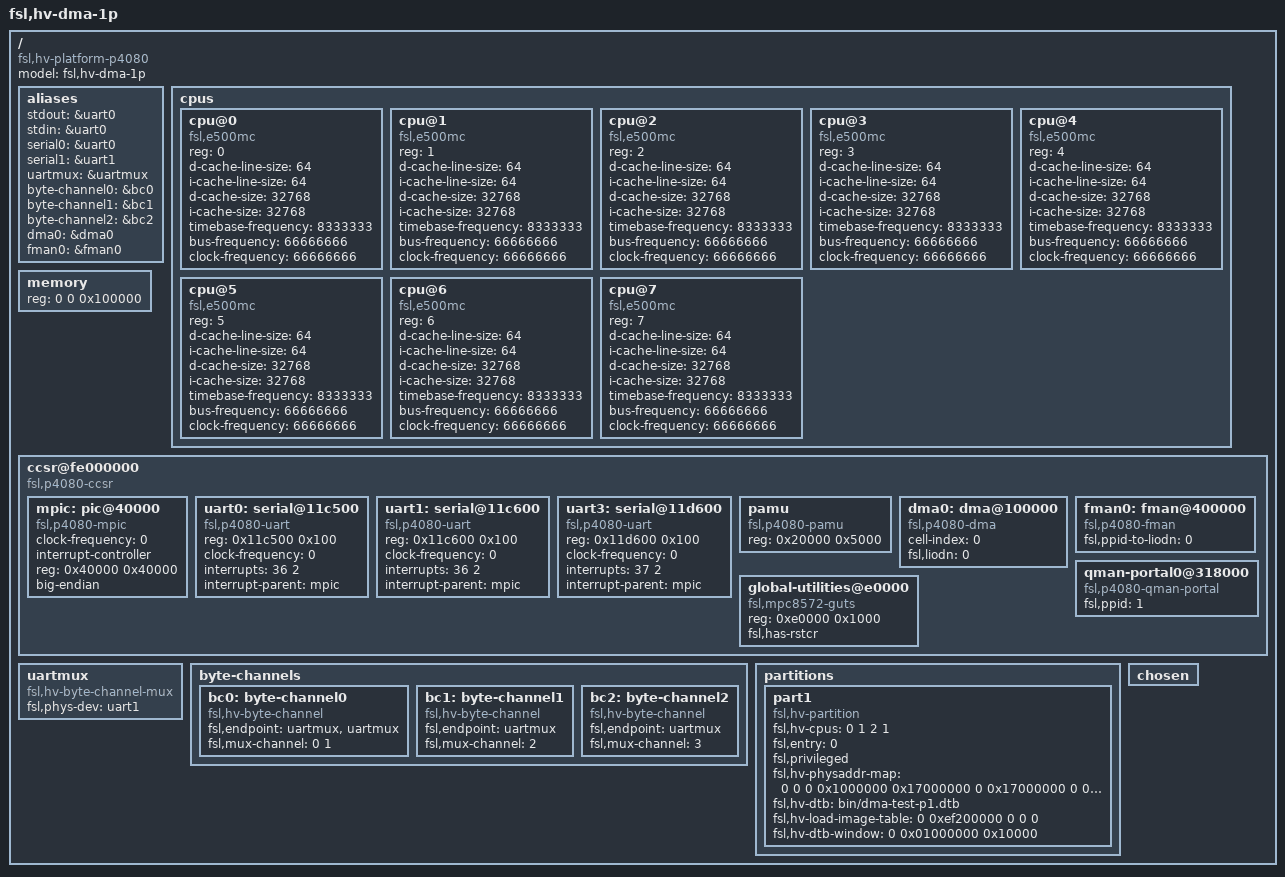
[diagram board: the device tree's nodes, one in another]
/dts-v1/;

/ {
	compatible = "fsl,hv-platform-p4080";
	model = "fsl,hv-dma-1p";
	#address-cells = <2>;
	#size-cells = <1>;

	aliases {
		stdout = &uart0;
		stdin = &uart0;
		serial0 = &uart0;
		serial1 = &uart1;
		uartmux = &uartmux;
		byte-channel0 = &bc0;
		byte-channel1 = &bc1;
		byte-channel2 = &bc2;
		dma0 = &dma0;
		fman0 = &fman0;
	};

	cpus {
		#address-cells = <1>;
		#size-cells = <0>;

		cpu@0 {
			device_type = "cpu";
			compatible = "fsl,e500mc";
			reg = <0>;
			d-cache-line-size = <64>;
			i-cache-line-size = <64>;
			d-cache-size = <32768>;
			i-cache-size = <32768>;
			timebase-frequency = <8333333>;
			bus-frequency = <66666666>;
			clock-frequency = <66666666>;
		};

		cpu@1 {
			device_type = "cpu";
			compatible = "fsl,e500mc";
			reg = <1>;
			d-cache-line-size = <64>;
			i-cache-line-size = <64>;
			d-cache-size = <32768>;
			i-cache-size = <32768>;
			timebase-frequency = <8333333>;
			bus-frequency = <66666666>;
			clock-frequency = <66666666>;
		};

		cpu@2 {
			device_type = "cpu";
			compatible = "fsl,e500mc";
			reg = <2>;
			d-cache-line-size = <64>;
			i-cache-line-size = <64>;
			d-cache-size = <32768>;
			i-cache-size = <32768>;
			timebase-frequency = <8333333>;
			bus-frequency = <66666666>;
			clock-frequency = <66666666>;
		};

		cpu@3 {
			device_type = "cpu";
			compatible = "fsl,e500mc";
			reg = <3>;
			d-cache-line-size = <64>;
			i-cache-line-size = <64>;
			d-cache-size = <32768>;
			i-cache-size = <32768>;
			timebase-frequency = <8333333>;
			bus-frequency = <66666666>;
			clock-frequency = <66666666>;
		};

		cpu@4 {
			device_type = "cpu";
			compatible = "fsl,e500mc";
			reg = <4>;
			d-cache-line-size = <64>;
			i-cache-line-size = <64>;
			d-cache-size = <32768>;
			i-cache-size = <32768>;
			timebase-frequency = <8333333>;
			bus-frequency = <66666666>;
			clock-frequency = <66666666>;
		};

		cpu@5 {
			device_type = "cpu";
			compatible = "fsl,e500mc";
			reg = <5>;
			d-cache-line-size = <64>;
			i-cache-line-size = <64>;
			d-cache-size = <32768>;
			i-cache-size = <32768>;
			timebase-frequency = <8333333>;
			bus-frequency = <66666666>;
			clock-frequency = <66666666>;
		};

		cpu@6 {
			device_type = "cpu";
			compatible = "fsl,e500mc";
			reg = <6>;
			d-cache-line-size = <64>;
			i-cache-line-size = <64>;
			d-cache-size = <32768>;
			i-cache-size = <32768>;
			timebase-frequency = <8333333>;
			bus-frequency = <66666666>;
			clock-frequency = <66666666>;
		};

		cpu@7 {
			device_type = "cpu";
			compatible = "fsl,e500mc";
			reg = <7>;
			d-cache-line-size = <64>;
			i-cache-line-size = <64>;
			d-cache-size = <32768>;
			i-cache-size = <32768>;
			timebase-frequency = <8333333>;
			bus-frequency = <66666666>;
			clock-frequency = <66666666>;
		};
	};

	memory {
		reg = <0 0 0x100000>;
		device_type = "memory";
	};

	ccsr@fe000000 {
		#address-cells = <1>;
		#size-cells = <1>;
		compatible = "fsl,p4080-ccsr", "simple-bus";
		ranges = <0 0 0xfe000000 0x400000>;

		mpic: pic@40000 {
			clock-frequency = <0>;
			interrupt-controller;
			#address-cells = <0>;
			#interrupt-cells = <2>;
			reg = <0x40000 0x40000>;
			compatible = "fsl,p4080-mpic", "fsl,mpic",
			             "chrp,open-pic";
			device_type = "open-pic";
			big-endian;
		};
		
		uart0: serial@11c500 {
			device_type = "serial";
			compatible = "fsl,p4080-uart", "fsl,ns16550", "ns16550";
			reg = <0x11c500 0x100>;
			clock-frequency = <0>;
			interrupts = <36 2>;
			interrupt-parent = <&mpic>;
		};

		uart1: serial@11c600 {
			device_type = "serial";
			compatible = "fsl,p4080-uart", "fsl,ns16550", "ns16550";
			reg = <0x11c600 0x100>;
			clock-frequency = <0>;
			interrupts = <36 2>;
			interrupt-parent = <&mpic>;
		};

		uart3: serial@11d600 {
			device_type = "serial";
			compatible = "fsl,p4080-uart", "fsl,ns16550", "ns16550";
			reg = <0x11d600 0x100>;
			clock-frequency = <0>;
			interrupts = <37 2>;
			interrupt-parent = <&mpic>;
		};

		pamu {

			compatible = "fsl,p4080-pamu";
			reg = <0x20000 0x5000>;
		};

		dma0: dma@100000 {
			#address-cells = <1>;
			#size-cells = <1>;
			compatible = "fsl,p4080-dma";
			cell-index = <0>;
			fsl,liodn = <0>;
		};

		fman0: fman@400000 {
			compatible = "fsl,p4080-fman";
			fsl,ppid-to-liodn = <0>;
		};

		qman-portal0@318000 {
			compatible = "fsl,p4080-qman-portal";
			fsl,ppid = <1>;
		};

		global-utilities@e0000 {	//global utilities block
			compatible = "fsl,mpc8572-guts";
			reg = <0xe0000 0x1000>;
			fsl,has-rstcr;
		};
	};

	uartmux: uartmux {
		compatible = "fsl,hv-byte-channel-mux";
		fsl,phys-dev = <&uart1>;
	};

	byte-channels {
		/* bc0 here is a weird case for testing purposes.
		 * It sets up a loopback in the mux, so that
		 * data coming in channel 0 goes out channel 1.
		 * bc0 is _not_ usable by a guest.
		 */
		bc0: byte-channel0 {
			compatible = "fsl,hv-byte-channel";
			fsl,endpoint = <&uartmux &uartmux>;
			fsl,mux-channel = <0 1>;
		};

		bc1: byte-channel1 {
			compatible = "fsl,hv-byte-channel";
			fsl,endpoint = <&uartmux>;
			fsl,mux-channel = <2>;
		};

		bc2: byte-channel2 {
			compatible = "fsl,hv-byte-channel";
			fsl,endpoint = <&uartmux>;
			fsl,mux-channel = <3>;
		};
	};

	partitions {
		part1 {
			compatible = "fsl,hv-partition";
			fsl,hv-cpus = <0 1 2 1>;
			fsl,entry = <0>;
			fsl,privileged;
			fsl,hv-physaddr-map = <0 0 0 0x1000000 0x17000000
			                       0 0x17000000 0 0x20000000 0x1000000>;
			fsl,hv-dtb = /incbin/("bin/dma-test-p1.dtb");
			fsl,hv-load-image-table = <0 0xef200000 0 0 0>;
			fsl,hv-dtb-window = <0 0x01000000 0x10000>;
		};
	};

	chosen {
	};
};
